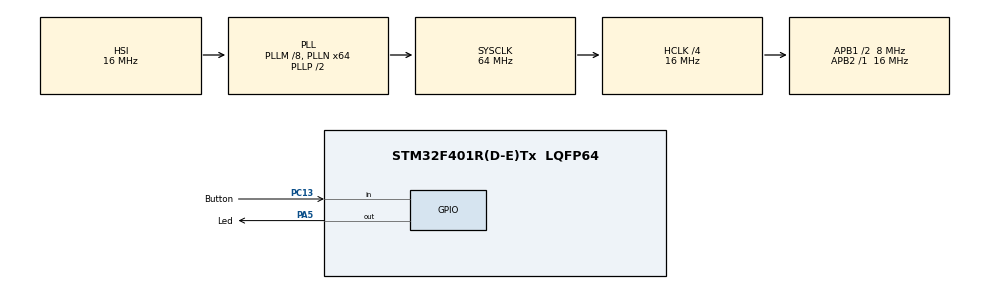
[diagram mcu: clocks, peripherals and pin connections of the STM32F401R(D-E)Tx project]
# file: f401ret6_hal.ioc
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FREERTOS.INCLUDE_vTaskDelayUntil=1
FREERTOS.Queues01=queButton,16,uint16_t,0,Dynamic,NULL,NULL
FREERTOS.Tasks01=defaultTask,0,128,StartDefaultTask,Default,NULL,Dynamic,NULL,NULL;Task_Led,0,128,Led,Default,NULL,Dynamic,NULL,NULL;Task_Button,0,128,Button,Default,NULL,Dynamic,NULL,NULL
FREERTOS.configENABLE_FPU=1
FREERTOS.configUSE_COUNTING_SEMAPHORES=1
FREERTOS.configUSE_NEWLIB_REENTRANT=1
Mcu.Family=STM32F4
Mcu.Name=STM32F401R(D-E)Tx
Mcu.Package=LQFP64
NVIC.PriorityGroup=NVIC_PRIORITYGROUP_4
NVIC.TIM1_UP_TIM10_IRQn=true\:15\:0\:false\:false\:true\:false\:false\:true\:true
NVIC.TimeBase=TIM1_UP_TIM10_IRQn
NVIC.TimeBaseIP=TIM1
PA13.Mode=Serial_Wire
PA13.Signal=SYS_JTMS-SWDIO
PA14.Mode=Serial_Wire
PA14.Signal=SYS_JTCK-SWCLK
PA2.Signal=USART2_TX
PA3.Signal=USART2_RX
PA5.GPIO_Label=Led
PA5.Signal=GPIO_Output
PC13-ANTI_TAMP.GPIO_Label=Button
PC13-ANTI_TAMP.Signal=GPIO_Input
PH0\ -\ OSC_IN.Mode=HSE-External-Clock-Source
PH0\ -\ OSC_IN.Signal=RCC_OSC_IN
PH1\ -\ OSC_OUT.Mode=HSE-External-Clock-Source
PH1\ -\ OSC_OUT.Signal=RCC_OSC_OUT
ProjectManager.HeapSize=0x200
ProjectManager.StackSize=0x400
ProjectManager.TargetToolchain=STM32CubeIDE
RCC.48MHZClocksFreq_Value=32000000
RCC.AHBCLKDivider=RCC_SYSCLK_DIV4
RCC.AHBFreq_Value=16000000
RCC.APB1CLKDivider=RCC_HCLK_DIV2
RCC.APB1Freq_Value=8000000
RCC.APB1TimFreq_Value=16000000
RCC.APB2Freq_Value=16000000
RCC.APB2TimFreq_Value=16000000
RCC.CortexFreq_Value=16000000
RCC.HCLKFreq_Value=16000000
RCC.HSE_VALUE=25000000
RCC.HSI_VALUE=16000000
RCC.LSE_VALUE=32768
RCC.PLLM=8
RCC.PLLN=64
RCC.SYSCLKFreq_VALUE=64000000
RCC.SYSCLKSource=RCC_SYSCLKSOURCE_PLLCLK
RCC.VCOOutputFreq_Value=128000000
VP_FREERTOS_VS_CMSIS_V1.Mode=CMSIS_V1
VP_SYS_VS_tim1.Mode=TIM1
board=custom

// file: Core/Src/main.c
/* USER CODE BEGIN Header */
/**
  ******************************************************************************
  * @file           : main.c
  * @brief          : Main program body
  ******************************************************************************
  * @attention
  *
  * Copyright (c) 2026 STMicroelectronics.
  * All rights reserved.
  *
  * This software is licensed under terms that can be found in the LICENSE file
  * in the root directory of this software component.
  * If no LICENSE file comes with this software, it is provided AS-IS.
  *
  ******************************************************************************
  */
/* USER CODE END Header */
#include "main.h"
#include "cmsis_os.h"
#include "gpio.h"

/* USER CODE BEGIN Includes */
#include "stdio.h"
#include "SEGGER_SYSVIEW.h"
/* USER CODE END Includes */

void SystemClock_Config(void);
void MX_FREERTOS_Init(void);

int main(void)
{

  /* MCU Configuration--------------------------------------------------------*/

  /* Reset of all peripherals, Initializes the Flash interface and the Systick. */
  HAL_Init();

  /* Configure the system clock */
  SystemClock_Config();

  /* Initialize all configured peripherals */
  MX_GPIO_Init();
  /* USER CODE BEGIN 2 */

  HAL_NVIC_SetPriorityGrouping(NVIC_PRIORITYGROUP_4);

  CoreDebug->DEMCR |= CoreDebug_DEMCR_TRCENA_Msk;
  DWT->CYCCNT = 0;
  DWT->CTRL |= DWT_CTRL_CYCCNTENA_Msk;

  SEGGER_SYSVIEW_Conf();
  //SEGGER_SYSVIEW_Start();

  /* USER CODE END 2 */

  /* Call init function for freertos objects (in cmsis_os2.c) */
  MX_FREERTOS_Init();

  /* Start scheduler */
  osKernelStart();

  /* We should never get here as control is now taken by the scheduler */

  /* Infinite loop */
  while (1)
  {

  }
}

void SystemClock_Config(void)
{
  RCC_OscInitTypeDef RCC_OscInitStruct = {0};
  RCC_ClkInitTypeDef RCC_ClkInitStruct = {0};

  /** Configure the main internal regulator output voltage
  */
  __HAL_RCC_PWR_CLK_ENABLE();
  __HAL_PWR_VOLTAGESCALING_CONFIG(PWR_REGULATOR_VOLTAGE_SCALE2);

  /** Initializes the RCC Oscillators according to the specified parameters
  * in the RCC_OscInitTypeDef structure.
  */
  RCC_OscInitStruct.OscillatorType = RCC_OSCILLATORTYPE_HSI;
  RCC_OscInitStruct.HSIState = RCC_HSI_ON;
  RCC_OscInitStruct.HSICalibrationValue = RCC_HSICALIBRATION_DEFAULT;
  RCC_OscInitStruct.PLL.PLLState = RCC_PLL_ON;
  RCC_OscInitStruct.PLL.PLLSource = RCC_PLLSOURCE_HSI;
  RCC_OscInitStruct.PLL.PLLM = 8;
  RCC_OscInitStruct.PLL.PLLN = 64;
  RCC_OscInitStruct.PLL.PLLP = RCC_PLLP_DIV2;
  RCC_OscInitStruct.PLL.PLLQ = 4;
  if (HAL_RCC_OscConfig(&RCC_OscInitStruct) != HAL_OK)
  {
    Error_Handler();
  }

  /** Initializes the CPU, AHB and APB buses clocks
  */
  RCC_ClkInitStruct.ClockType = RCC_CLOCKTYPE_HCLK|RCC_CLOCKTYPE_SYSCLK
                              |RCC_CLOCKTYPE_PCLK1|RCC_CLOCKTYPE_PCLK2;
  RCC_ClkInitStruct.SYSCLKSource = RCC_SYSCLKSOURCE_PLLCLK;
  RCC_ClkInitStruct.AHBCLKDivider = RCC_SYSCLK_DIV4;
  RCC_ClkInitStruct.APB1CLKDivider = RCC_HCLK_DIV2;
  RCC_ClkInitStruct.APB2CLKDivider = RCC_HCLK_DIV1;

  if (HAL_RCC_ClockConfig(&RCC_ClkInitStruct, FLASH_LATENCY_0) != HAL_OK)
  {
    Error_Handler();
  }
}

void HAL_TIM_PeriodElapsedCallback(TIM_HandleTypeDef *htim)
{
  if (htim->Instance == TIM1)
  {
    HAL_IncTick();
  }
}

void Error_Handler(void)
{
  __disable_irq();
  while (1)
  {
  }
}

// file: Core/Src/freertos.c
/* USER CODE BEGIN Header */
/**
  ******************************************************************************
  * File Name          : freertos.c
  * Description        : Code for freertos applications
  ******************************************************************************
  * @attention
  *
  * Copyright (c) 2026 STMicroelectronics.
  * All rights reserved.
  *
  * This software is licensed under terms that can be found in the LICENSE file
  * in the root directory of this software component.
  * If no LICENSE file comes with this software, it is provided AS-IS.
  *
  ******************************************************************************
  */
/* USER CODE END Header */

#include "FreeRTOS.h"
#include "task.h"
#include "main.h"
#include "cmsis_os.h"

osThreadId defaultTaskHandle;
osThreadId Task_LedHandle;
osThreadId Task_ButtonHandle;
osMessageQId queButtonHandle;

void StartDefaultTask(void const * argument);
void Led(void const * argument);
void Button(void const * argument);

void MX_FREERTOS_Init(void); /* (MISRA C 2004 rule 8.1) */

/* GetIdleTaskMemory prototype (linked to static allocation support) */
void vApplicationGetIdleTaskMemory( StaticTask_t **ppxIdleTaskTCBBuffer, StackType_t **ppxIdleTaskStackBuffer, uint32_t *pulIdleTaskStackSize );

/* USER CODE BEGIN GET_IDLE_TASK_MEMORY */
static StaticTask_t xIdleTaskTCBBuffer;
static StackType_t xIdleStack[configMINIMAL_STACK_SIZE];

void vApplicationGetIdleTaskMemory( StaticTask_t **ppxIdleTaskTCBBuffer, StackType_t **ppxIdleTaskStackBuffer, uint32_t *pulIdleTaskStackSize )
{
  *ppxIdleTaskTCBBuffer = &xIdleTaskTCBBuffer;
  *ppxIdleTaskStackBuffer = &xIdleStack[0];
  *pulIdleTaskStackSize = configMINIMAL_STACK_SIZE;
  /* place for user code */
}
/* USER CODE END GET_IDLE_TASK_MEMORY */

void MX_FREERTOS_Init(void) {

  /* Create the queue(s) */
  /* definition and creation of queButton */
  osMessageQDef(queButton, 16, uint16_t);
  queButtonHandle = osMessageCreate(osMessageQ(queButton), NULL);

  /* Create the thread(s) */
  /* definition and creation of defaultTask */
  osThreadDef(defaultTask, StartDefaultTask, osPriorityNormal, 0, 128);
  defaultTaskHandle = osThreadCreate(osThread(defaultTask), NULL);

  /* definition and creation of Task_Led */
  osThreadDef(Task_Led, Led, osPriorityNormal, 0, 128);
  Task_LedHandle = osThreadCreate(osThread(Task_Led), NULL);

  /* definition and creation of Task_Button */
  osThreadDef(Task_Button, Button, osPriorityNormal, 0, 128);
  Task_ButtonHandle = osThreadCreate(osThread(Task_Button), NULL);

}

void StartDefaultTask(void const * argument)
{
  /* USER CODE BEGIN StartDefaultTask */
  /* Infinite loop */
  for(;;)
  {
    osDelay(10);
  }
  /* USER CODE END StartDefaultTask */
}

void Led(void const * argument)
{
  /* USER CODE BEGIN Led */
  /* Infinite loop */
  for(;;)
  {

	  osDelay(20);
  }
  /* USER CODE END Led */
}

void Button(void const * argument)
{
  /* USER CODE BEGIN Button */
  /* Infinite loop */
  for(;;)
  {
	  HAL_GPIO_TogglePin(Led_GPIO_Port, Led_Pin);
	  osDelay(30);
  }
  /* USER CODE END Button */
}
